# PIC32MK0512MCM064 register map
Vendor: Microchip
Registers are 32-bit, read-write, reset 0x0 unless marked. A register's access mark holds for its fields unless they carry their own. Addresses are absolute, and some are shared; only a register's first bit layout is shown; [hi:lo] are bit positions; {n}, {i} and the like mark numbered series.

## CFG
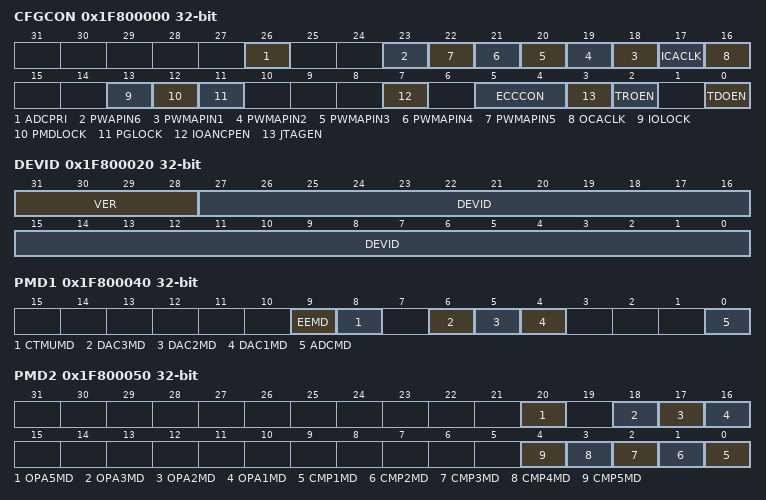
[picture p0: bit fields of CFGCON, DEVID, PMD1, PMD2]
0x1F800000 CFGCON reset not defined — (power-on value -----0--xxxxxx00--000---0-xx00-1)
  [26] ADCPRI
  [23] PWAPIN6 — PWM Alternate I/O Pin Select
  [n+17] PWMAPIN{n} (n=1..5) — PWM Alternate I/O Pin Select
  [17] ICACLK
  [16] OCACLK
  [13] IOLOCK
  [12] PMDLOCK
  [11] PGLOCK
  [7] IOANCPEN
  [5:4] ECCCON — Flash ECC Configuration Bits
  [3] JTAGEN
  [2] TROEN
  [0] TDOEN
0x1F800020 DEVID reset not defined — (power-on value 0000xxxxxxxxxxxxxxxxxxxxxxxxxxxx)
  [31:28] VER ro, [27:0] DEVID
0x1F800030 SYSKEY
0x1F800040 PMD1 reset not defined — (power-on value ----------------------xx-xxx---0)
  [9] EEMD, [8] CTMUMD, [6] DAC3MD, [5] DAC2MD, [4] DAC1MD, [0] ADCMD
0x1F800050 PMD2 reset not defined — (power-on value -----------x-xxx-----------xxx00)
  [20] OPA5MD, [18] OPA3MD, [17] OPA2MD, [16] OPA1MD, [n-1] CMP{n}MD (n=1..5)
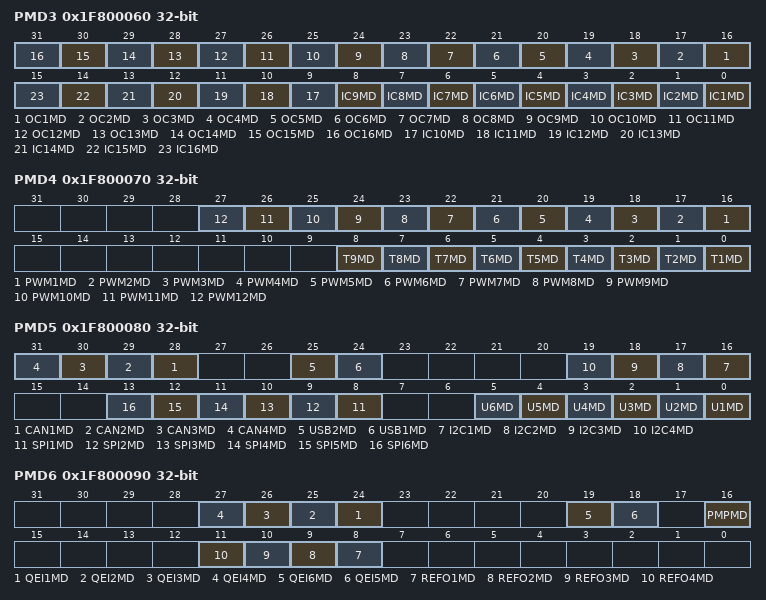
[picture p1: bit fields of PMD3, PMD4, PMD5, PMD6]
0x1F800060 PMD3 reset not defined — (power-on value xxxxxxx000000000xxxxxxx000000000)
  [n+15] OC{n}MD (n=1..16), [n-1] IC{n}MD (n=1..16)
0x1F800070 PMD4 reset not defined — (power-on value ----xxxxxxxxxxxx-------111111111)
  [n+15] PWM{n}MD (n=1..12), [n-1] T{n}MD (n=1..9)
0x1F800080 PMD5 reset not defined — (power-on value xxx0--xx----xx00--xxxx00--xxxx00)
  [n+27] CAN{n}MD (n=1..4), [25] USB2MD, [24] USB1MD, [n+15] I2C{n}MD (n=1..4), [n+7] SPI{n}MD (n=1..6), [n-1] U{n}MD (n=1..6)
0x1F800090 PMD6 reset not defined — (power-on value ----xxxx----xx-x----0000-------0)
  [n+23] QEI{n}MD (n=1..4), [19] QEI6MD, [18] QEI5MD, [16] PMPMD, [n+7] REFO{n}MD (n=1..4)
0x1F8000A0 PMD7
  [4] DMAMD
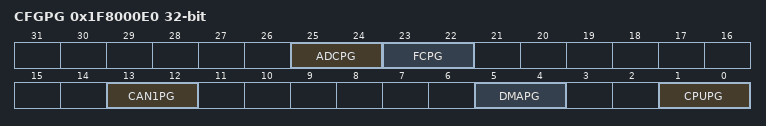
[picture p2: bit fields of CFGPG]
0x1F8000E0 CFGPG
  [25:24] ADCPG, [23:22] FCPG, [13:12] CAN1PG, [5:4] DMAPG, [1:0] CPUPG
0x1F800100 CFGAPP2 reset not defined — (power-on value ----------x---------------------)
  [21] POSCFAIL — Primary Oscillator Unable to Lock Status Read-only bit
    1=Crystal or Resonator usage failed; 0=Crystal or resonator is locked or is indeterminate. If successfully locked, clock status is determined bythe SPLLRDY (CLKSTAT<7>) status flag.
0x1F800110 CFGCON2 reset not defined — (power-on value ------------------------xxxxxxxx)
  [7:0] EEWS — Read Access Count bits

## PCACHE
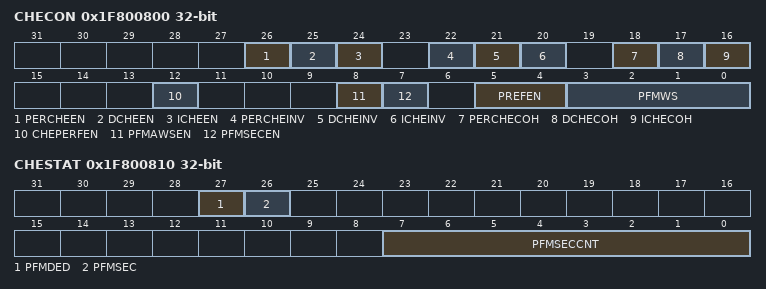
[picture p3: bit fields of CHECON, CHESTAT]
0x1F800800 CHECON reset not defined — (power-on value -----111-000-000---0---1x-00xxxx)
  [26] PERCHEEN, [25] DCHEEN, [24] ICHEEN, [22] PERCHEINV, [21] DCHEINV, [20] ICHEINV, [18] PERCHECOH, [17] DCHECOH, [16] ICHECOH, [12] CHEPERFEN, [8] PFMAWSEN, [7] PFMSECEN, [5:4] PREFEN, [3:0] PFMWS
0x1F800810 CHESTAT reset not defined — (power-on value ----xx------------------xxxxxxxx)
  [27] PFMDED, [26] PFMSEC, [7:0] PFMSECCNT
0x1F800820 CHEHIT reset not defined — (power-on value xxxxxxxxxxxxxxxxxxxxxxxxxxxxxxxx)
  [31:0] CHEHIT — (can only be cleared)
0x1F800830 CHEMIS reset not defined — (power-on value xxxxxxxxxxxxxxxxxxxxxxxxxxxxxxxx)
  [31:0] CHEMIS — (can only be cleared)

## NVM
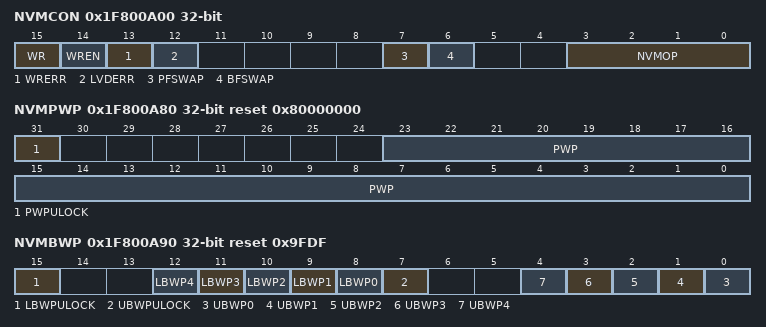
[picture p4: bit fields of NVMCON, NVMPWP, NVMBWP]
0x1F800A00 NVMCON reset not defined — (power-on value ----------------0000----0x--0000)
  [15] WR, [14] WREN, [13] WRERR, [12] LVDERR, [7] PFSWAP, [6] BFSWAP, [3:0] NVMOP
0x1F800A10 NVMKEY wo
0x1F800A20 NVMADDR
{0x1F800A30+0x10*i} NVMDATA{i} (i=0..3)
0x1F800A70 NVMSRCADDR
0x1F800A80 NVMPWP reset 0x80000000
  [31] PWPULOCK, [23:0] PWP
0x1F800A90 NVMBWP reset 0x9FDF
  [15] LBWPULOCK, [n+8] LBWP{n} (n=0..4), [7] UBWPULOCK, [n] UBWP{n} (n=0..4)
0x1F800AA0 NVMCON2 reset not defined — (power-on value xxxx-------xxxxxx-xx--xx00------)
  [7:6] SWAPLOCK

## WDT
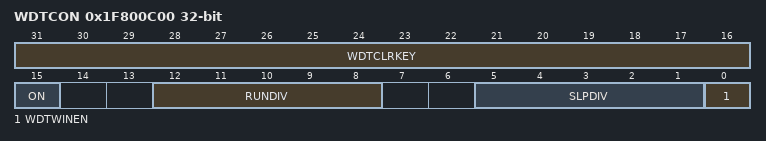
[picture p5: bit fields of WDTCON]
0x1F800C00 WDTCON reset not defined — (power-on value 0000000000000000x--xxxxx--xxxxx0)
  [31:16] WDTCLRKEY wo, [15] ON, [12:8] RUNDIV ro, [5:1] SLPDIV ro, [0] WDTWINEN

## DMT
0x1F800E00 DMTCON
  [15] ON
0x1F800E10 DMTPRECLR
  [15:8] STEP1
0x1F800E20 DMTCLR
  [7:0] STEP2
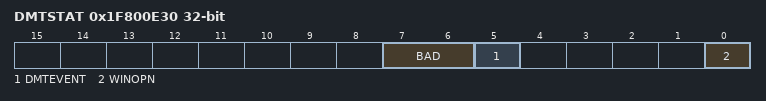
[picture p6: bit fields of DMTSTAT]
0x1F800E30 DMTSTAT ro
  [7:6] BAD, [5] DMTEVENT, [0] WINOPN
0x1F800E40 DMTCNT ro
  [31:0] COUNTER
0x1F800E60 DMTPSCNT ro reset not defined — (power-on value xxxxxxxxxxxxxxxxxxxxxxxxxxxxxxxx)
  [31:0] PSCNT
0x1F800E70 DMTPSINTV ro reset not defined — (power-on value xxxxxxxxxxxxxxxxxxxxxxxxxxxxxxxx)
  [31:0] PSINTV
